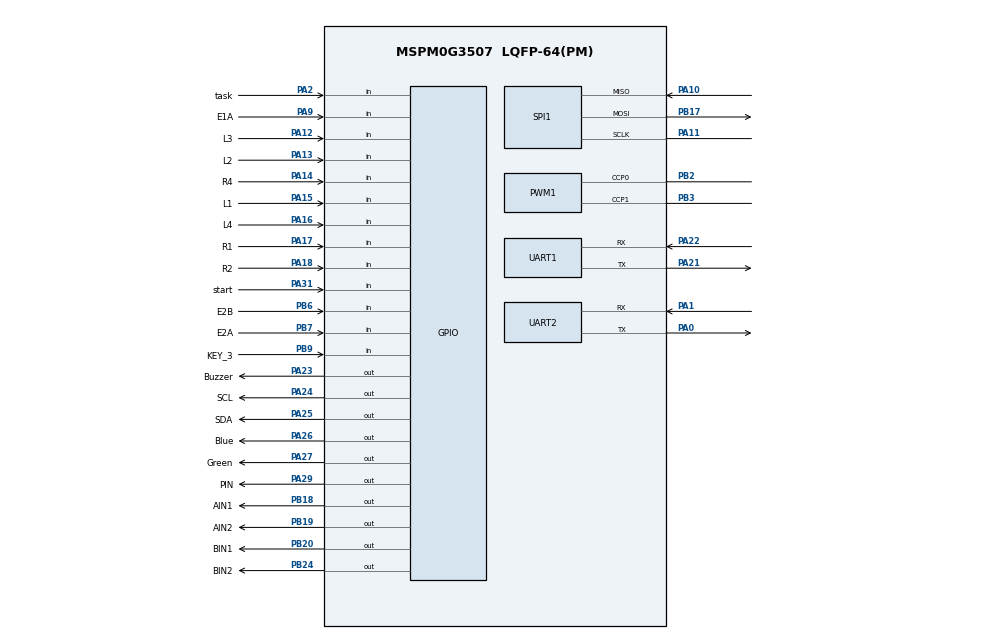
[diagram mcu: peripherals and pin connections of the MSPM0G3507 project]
/**
 * These arguments were used when this file was generated. They will be automatically applied on subsequent loads
 * via the GUI or CLI. Run CLI with '--help' for additional information on how to override these arguments.
 * @cliArgs --device "MSPM0G350X" --part "Default" --package "LQFP-64(PM)" --product "mspm0_sdk@2.02.00.05"
 * @v2CliArgs --device "MSPM0G3507" --package "LQFP-64(PM)" --product "mspm0_sdk@2.02.00.05"
 * @versions {"tool":"1.21.1+3772"}
 */

/**
 * Import the modules used in this configuration.
 */
const GPIO    = scripting.addModule("/ti/driverlib/GPIO", {}, false);
const GPIO1   = GPIO.addInstance();
const GPIO2   = GPIO.addInstance();
const GPIO3   = GPIO.addInstance();
const GPIO4   = GPIO.addInstance();
const GPIO5   = GPIO.addInstance();
const GPIO6   = GPIO.addInstance();
const GPIO7   = GPIO.addInstance();
const GPIO8   = GPIO.addInstance();
const GPIO9   = GPIO.addInstance();
const GPIO10  = GPIO.addInstance();
const GPIO11  = GPIO.addInstance();
const GPIO12  = GPIO.addInstance();
const GPIO13  = GPIO.addInstance();
const PWM     = scripting.addModule("/ti/driverlib/PWM", {}, false);
const PWM1    = PWM.addInstance();
const SPI     = scripting.addModule("/ti/driverlib/SPI", {}, false);
const SPI1    = SPI.addInstance();
const SYSCTL  = scripting.addModule("/ti/driverlib/SYSCTL");
const SYSTICK = scripting.addModule("/ti/driverlib/SYSTICK");
const TIMER   = scripting.addModule("/ti/driverlib/TIMER", {}, false);
const TIMER1  = TIMER.addInstance();
const TIMER2  = TIMER.addInstance();
const TIMER3  = TIMER.addInstance();
const TIMER4  = TIMER.addInstance();
const UART    = scripting.addModule("/ti/driverlib/UART", {}, false);
const UART1   = UART.addInstance();
const UART2   = UART.addInstance();

/**
 * Write custom configuration values to the imported modules.
 */
const divider9       = system.clockTree["UDIV"];
divider9.divideValue = 2;

const gate7  = system.clockTree["MFCLKGATE"];
gate7.enable = true;

const mux4       = system.clockTree["EXHFMUX"];
mux4.inputSelect = "EXHFMUX_XTAL";

const mux8       = system.clockTree["HSCLKMUX"];
mux8.inputSelect = "HSCLKMUX_SYSPLL2X";

const mux12       = system.clockTree["SYSPLLMUX"];
mux12.inputSelect = "zSYSPLLMUX_HFCLK";

const pinFunction4     = system.clockTree["HFXT"];
pinFunction4.inputFreq = 40;
pinFunction4.enable    = true;

GPIO1.port                               = "PORTA";
GPIO1.$name                              = "LED";
GPIO1.associatedPins.create(2);
GPIO1.associatedPins[0].internalResistor = "PULL_DOWN";
GPIO1.associatedPins[0].$name            = "Blue";
GPIO1.associatedPins[0].assignedPin      = "26";
GPIO1.associatedPins[0].pin.$assign      = "PA26";
GPIO1.associatedPins[1].$name            = "Green";
GPIO1.associatedPins[1].assignedPin      = "27";
GPIO1.associatedPins[1].pin.$assign      = "PA27";

const Board = scripting.addModule("/ti/driverlib/Board", {}, false);

GPIO2.port                               = "PORTA";
GPIO2.$name                              = "KEY";
GPIO2.associatedPins.create(2);
GPIO2.associatedPins[0].direction        = "INPUT";
GPIO2.associatedPins[0].$name            = "task";
GPIO2.associatedPins[0].internalResistor = "PULL_UP";
GPIO2.associatedPins[0].inputFilter      = "8_CYCLES";
GPIO2.associatedPins[0].assignedPin      = "02";
GPIO2.associatedPins[0].pin.$assign      = "PA2";
GPIO2.associatedPins[1].direction        = "INPUT";
GPIO2.associatedPins[1].$name            = "start";
GPIO2.associatedPins[1].internalResistor = "PULL_UP";
GPIO2.associatedPins[1].inputFilter      = "8_CYCLES";
GPIO2.associatedPins[1].assignedPin      = "31";
GPIO2.associatedPins[1].pin.$assign      = "PA31";

GPIO3.port                           = "PORTA";
GPIO3.$name                          = "BUZZER";
GPIO3.associatedPins[0].$name        = "Buzzer";
GPIO3.associatedPins[0].assignedPin  = "23";
GPIO3.associatedPins[0].initialValue = "SET";
GPIO3.associatedPins[0].pin.$assign  = "PA23";

GPIO4.$name                          = "Motor_left";
GPIO4.port                           = "PORTB";
GPIO4.associatedPins.create(2);
GPIO4.associatedPins[0].initialValue = "SET";
GPIO4.associatedPins[0].$name        = "AIN1";
GPIO4.associatedPins[0].assignedPin  = "18";
GPIO4.associatedPins[0].pin.$assign  = "PB18";
GPIO4.associatedPins[1].$name        = "AIN2";
GPIO4.associatedPins[1].initialValue = "SET";
GPIO4.associatedPins[1].assignedPin  = "19";
GPIO4.associatedPins[1].pin.$assign  = "PB19";

GPIO5.$name                          = "Motor_right";
GPIO5.associatedPins.create(2);
GPIO5.associatedPins[0].$name        = "BIN1";
GPIO5.associatedPins[0].initialValue = "SET";
GPIO5.associatedPins[0].assignedPort = "PORTB";
GPIO5.associatedPins[0].assignedPin  = "20";
GPIO5.associatedPins[0].pin.$assign  = "PB20";
GPIO5.associatedPins[1].$name        = "BIN2";
GPIO5.associatedPins[1].initialValue = "SET";
GPIO5.associatedPins[1].assignedPort = "PORTB";
GPIO5.associatedPins[1].assignedPin  = "24";
GPIO5.associatedPins[1].pin.$assign  = "PB24";

GPIO6.$name                               = "Encoder_left";
GPIO6.port                                = "PORTA";
GPIO6.associatedPins.create(2);
GPIO6.associatedPins[0].direction         = "INPUT";
GPIO6.associatedPins[0].$name             = "E1A";
GPIO6.associatedPins[0].assignedPin       = "9";
GPIO6.associatedPins[0].interruptEn       = true;
GPIO6.associatedPins[0].interruptPriority = "0";
GPIO6.associatedPins[0].polarity          = "RISE";
GPIO6.associatedPins[0].pin.$assign       = "PA9";
GPIO6.associatedPins[1].$name             = "E1B";
GPIO6.associatedPins[1].direction         = "INPUT";
GPIO6.associatedPins[1].assignedPin       = "8";
GPIO6.associatedPins[1].interruptEn       = true;
GPIO6.associatedPins[1].interruptPriority = "0";
GPIO6.associatedPins[1].polarity          = "RISE";

GPIO7.$name                               = "Encoder_right";
GPIO7.port                                = "PORTB";
GPIO7.associatedPins.create(2);
GPIO7.associatedPins[0].$name             = "E2A";
GPIO7.associatedPins[0].direction         = "INPUT";
GPIO7.associatedPins[0].interruptEn       = true;
GPIO7.associatedPins[0].assignedPin       = "7";
GPIO7.associatedPins[0].interruptPriority = "0";
GPIO7.associatedPins[0].polarity          = "RISE";
GPIO7.associatedPins[0].pin.$assign       = "PB7";
GPIO7.associatedPins[1].$name             = "E2B";
GPIO7.associatedPins[1].direction         = "INPUT";
GPIO7.associatedPins[1].interruptEn       = true;
GPIO7.associatedPins[1].assignedPin       = "6";
GPIO7.associatedPins[1].interruptPriority = "0";
GPIO7.associatedPins[1].polarity          = "RISE";
GPIO7.associatedPins[1].pin.$assign       = "PB6";

GPIO8.port                          = "PORTA";
GPIO8.$name                         = "Gray_IOA";
GPIO8.associatedPins.create(7);
GPIO8.associatedPins[0].direction   = "INPUT";
GPIO8.associatedPins[0].$name       = "L4";
GPIO8.associatedPins[0].assignedPin = "16";
GPIO8.associatedPins[0].pin.$assign = "PA16";
GPIO8.associatedPins[1].direction   = "INPUT";
GPIO8.associatedPins[1].$name       = "L3";
GPIO8.associatedPins[1].assignedPin = "12";
GPIO8.associatedPins[1].pin.$assign = "PA12";
GPIO8.associatedPins[2].direction   = "INPUT";
GPIO8.associatedPins[2].$name       = "L2";
GPIO8.associatedPins[2].assignedPin = "13";
GPIO8.associatedPins[2].pin.$assign = "PA13";
GPIO8.associatedPins[3].direction   = "INPUT";
GPIO8.associatedPins[3].$name       = "L1";
GPIO8.associatedPins[3].assignedPin = "15";
GPIO8.associatedPins[3].pin.$assign = "PA15";
GPIO8.associatedPins[4].direction   = "INPUT";
GPIO8.associatedPins[4].assignedPin = "17";
GPIO8.associatedPins[4].$name       = "R1";
GPIO8.associatedPins[4].pin.$assign = "PA17";
GPIO8.associatedPins[5].direction   = "INPUT";
GPIO8.associatedPins[5].assignedPin = "18";
GPIO8.associatedPins[5].$name       = "R2";
GPIO8.associatedPins[5].pin.$assign = "PA18";
GPIO8.associatedPins[6].$name       = "R4";
GPIO8.associatedPins[6].assignedPin = "14";
GPIO8.associatedPins[6].direction   = "INPUT";
GPIO8.associatedPins[6].pin.$assign = "PA14";

GPIO9.port                          = "PORTB";
GPIO9.$name                         = "Gray_IOB";
GPIO9.associatedPins[0].direction   = "INPUT";
GPIO9.associatedPins[0].assignedPin = "08";
GPIO9.associatedPins[0].$name       = "R3";

GPIO10.$name                          = "SR04";
GPIO10.associatedPins.create(2);
GPIO10.associatedPins[0].$name        = "Trig";
GPIO10.associatedPins[0].initialValue = "SET";
GPIO10.associatedPins[0].assignedPort = "PORTA";
GPIO10.associatedPins[0].assignedPin  = "7";
GPIO10.associatedPins[1].$name        = "Echo";
GPIO10.associatedPins[1].assignedPort = "PORTA";
GPIO10.associatedPins[1].assignedPin  = "28";
GPIO10.associatedPins[1].initialValue = "SET";
GPIO10.associatedPins[1].direction    = "INPUT";

GPIO11.$name                         = "KEY3";
GPIO11.port                          = "PORTB";
GPIO11.associatedPins[0].$name       = "KEY_3";
GPIO11.associatedPins[0].direction   = "INPUT";
GPIO11.associatedPins[0].assignedPin = "9";
GPIO11.associatedPins[0].pin.$assign = "PB9";

GPIO12.$name                          = "OLED";
GPIO12.port                           = "PORTA";
GPIO12.associatedPins.create(2);
GPIO12.associatedPins[0].$name        = "SCL";
GPIO12.associatedPins[0].initialValue = "SET";
GPIO12.associatedPins[0].assignedPin  = "24";
GPIO12.associatedPins[0].pin.$assign  = "PA24";
GPIO12.associatedPins[1].$name        = "SDA";
GPIO12.associatedPins[1].initialValue = "SET";
GPIO12.associatedPins[1].assignedPin  = "25";
GPIO12.associatedPins[1].pin.$assign  = "PA25";

GPIO13.$name                          = "CS";
GPIO13.associatedPins[0].$name        = "PIN";
GPIO13.associatedPins[0].assignedPort = "PORTA";
GPIO13.associatedPins[0].assignedPin  = "29";
GPIO13.associatedPins[0].pin.$assign  = "PA29";

PWM1.$name                              = "PWM";
PWM1.clockDivider                       = 8;
PWM1.pwmMode                            = "EDGE_ALIGN_UP";
PWM1.timerStartTimer                    = true;
PWM1.clockPrescale                      = 4;
PWM1.peripheral.$assign                 = "TIMG6";
PWM1.peripheral.ccp0Pin.$assign         = "PB2";
PWM1.peripheral.ccp1Pin.$assign         = "PB3";
PWM1.PWM_CHANNEL_0.$name                = "ti_driverlib_pwm_PWMTimerCC0";
PWM1.PWM_CHANNEL_1.$name                = "ti_driverlib_pwm_PWMTimerCC1";
PWM1.ccp0PinConfig.direction            = scripting.forceWrite("OUTPUT");
PWM1.ccp0PinConfig.hideOutputInversion  = scripting.forceWrite(false);
PWM1.ccp0PinConfig.onlyInternalResistor = scripting.forceWrite(false);
PWM1.ccp0PinConfig.passedPeripheralType = scripting.forceWrite("Digital");
PWM1.ccp0PinConfig.$name                = "ti_driverlib_gpio_GPIOPinGeneric2";
PWM1.ccp1PinConfig.direction            = scripting.forceWrite("OUTPUT");
PWM1.ccp1PinConfig.hideOutputInversion  = scripting.forceWrite(false);
PWM1.ccp1PinConfig.onlyInternalResistor = scripting.forceWrite(false);
PWM1.ccp1PinConfig.passedPeripheralType = scripting.forceWrite("Digital");
PWM1.ccp1PinConfig.$name                = "ti_driverlib_gpio_GPIOPinGeneric3";

SPI1.$name                              = "SPI";
SPI1.targetBitRate                      = 2000000;
SPI1.polarity                           = "1";
SPI1.phase                              = "1";
SPI1.peripheral.$assign                 = "SPI0";
SPI1.peripheral.sclkPin.$assign         = "PA11";
SPI1.peripheral.mosiPin.$assign         = "PB17";
SPI1.peripheral.misoPin.$assign         = "PA10";
SPI1.sclkPinConfig.direction            = scripting.forceWrite("OUTPUT");
SPI1.sclkPinConfig.onlyInternalResistor = scripting.forceWrite(false);
SPI1.sclkPinConfig.passedPeripheralType = scripting.forceWrite("Digital");
SPI1.sclkPinConfig.$name                = "ti_driverlib_gpio_GPIOPinGeneric6";
SPI1.mosiPinConfig.direction            = scripting.forceWrite("OUTPUT");
SPI1.mosiPinConfig.hideOutputInversion  = scripting.forceWrite(false);
SPI1.mosiPinConfig.onlyInternalResistor = scripting.forceWrite(false);
SPI1.mosiPinConfig.passedPeripheralType = scripting.forceWrite("Digital");
SPI1.mosiPinConfig.$name                = "ti_driverlib_gpio_GPIOPinGeneric7";
SPI1.misoPinConfig.onlyInternalResistor = scripting.forceWrite(false);
SPI1.misoPinConfig.passedPeripheralType = scripting.forceWrite("Digital");
SPI1.misoPinConfig.$name                = "ti_driverlib_gpio_GPIOPinGeneric8";
SPI1.cs0PinConfig.direction             = scripting.forceWrite("OUTPUT");
SPI1.cs0PinConfig.hideOutputInversion   = scripting.forceWrite(false);
SPI1.cs0PinConfig.onlyInternalResistor  = scripting.forceWrite(false);
SPI1.cs0PinConfig.passedPeripheralType  = scripting.forceWrite("Digital");
SPI1.cs0PinConfig.$name                 = "ti_driverlib_gpio_GPIOPinGeneric9";

SYSCTL.forceDefaultClkConfig = true;
SYSCTL.clockTreeEn           = true;

SYSTICK.periodEnable      = true;
SYSTICK.systickEnable     = true;
SYSTICK.interruptPriority = "0";
SYSTICK.period            = 32;

TIMER1.$name              = "TIMER_0";
TIMER1.timerClkDiv        = 8;
TIMER1.timerClkPrescale   = 100;
TIMER1.timerMode          = "PERIODIC";
TIMER1.interrupts         = ["ZERO"];
TIMER1.timerStartTimer    = true;
TIMER1.timerPeriod        = "10ms";
TIMER1.interruptPriority  = "0";
TIMER1.peripheral.$assign = "TIMA0";

TIMER2.$name              = "TIMER_1";
TIMER2.timerStartTimer    = true;
TIMER2.timerMode          = "PERIODIC";
TIMER2.timerClkDiv        = 8;
TIMER2.timerClkPrescale   = 100;
TIMER2.interrupts         = ["LOAD"];
TIMER2.interruptPriority  = "1";
TIMER2.timerPeriod        = "10ms";
TIMER2.peripheral.$assign = "TIMG0";

TIMER3.$name              = "TIMER_2";
TIMER3.timerClkDiv        = 4;
TIMER3.timerClkPrescale   = 10;
TIMER3.timerMode          = "PERIODIC_UP";
TIMER3.timerStartTimer    = true;
TIMER3.timerPeriod        = "1ms";
TIMER3.interruptPriority  = "2";
TIMER3.interrupts         = ["LOAD"];
TIMER3.peripheral.$assign = "TIMA1";

TIMER4.$name              = "TIMER_3";
TIMER4.timerMode          = "PERIODIC";
TIMER4.timerPeriod        = "100us";
TIMER4.timerStartTimer    = true;
TIMER4.interrupts         = ["ZERO"];
TIMER4.interruptPriority  = "2";
TIMER4.peripheral.$assign = "TIMG7";

UART1.$name                            = "UART_2";
UART1.targetBaudRate                   = 115200;
UART1.enabledInterrupts                = ["RX"];
UART1.interruptPriority                = "0";
UART1.uartClkSrc                       = "MFCLK";
UART1.peripheral.$assign               = "UART2";
UART1.peripheral.rxPin.$assign         = "PA22";
UART1.peripheral.txPin.$assign         = "PA21";
UART1.txPinConfig.direction            = scripting.forceWrite("OUTPUT");
UART1.txPinConfig.hideOutputInversion  = scripting.forceWrite(false);
UART1.txPinConfig.onlyInternalResistor = scripting.forceWrite(false);
UART1.txPinConfig.passedPeripheralType = scripting.forceWrite("Digital");
UART1.txPinConfig.$name                = "ti_driverlib_gpio_GPIOPinGeneric0";
UART1.rxPinConfig.hideOutputInversion  = scripting.forceWrite(false);
UART1.rxPinConfig.onlyInternalResistor = scripting.forceWrite(false);
UART1.rxPinConfig.passedPeripheralType = scripting.forceWrite("Digital");
UART1.rxPinConfig.$name                = "ti_driverlib_gpio_GPIOPinGeneric1";

UART2.$name                            = "UART_0";
UART2.targetBaudRate                   = 115200;
UART2.enabledInterrupts                = ["RX"];
UART2.interruptPriority                = "1";
UART2.peripheral.$assign               = "UART0";
UART2.peripheral.rxPin.$assign         = "PA1";
UART2.peripheral.txPin.$assign         = "PA0";
UART2.txPinConfig.direction            = scripting.forceWrite("OUTPUT");
UART2.txPinConfig.hideOutputInversion  = scripting.forceWrite(false);
UART2.txPinConfig.onlyInternalResistor = scripting.forceWrite(false);
UART2.txPinConfig.passedPeripheralType = scripting.forceWrite("Digital");
UART2.txPinConfig.$name                = "ti_driverlib_gpio_GPIOPinGeneric4";
UART2.rxPinConfig.hideOutputInversion  = scripting.forceWrite(false);
UART2.rxPinConfig.onlyInternalResistor = scripting.forceWrite(false);
UART2.rxPinConfig.passedPeripheralType = scripting.forceWrite("Digital");
UART2.rxPinConfig.$name                = "ti_driverlib_gpio_GPIOPinGeneric5";

/**
 * Pinmux solution for unlocked pins/peripherals. This ensures that minor changes to the automatic solver in a future
 * version of the tool will not impact the pinmux you originally saw.  These lines can be completely deleted in order to
 * re-solve from scratch.
 */
pinFunction4.peripheral.$suggestSolution           = "SYSCTL";
pinFunction4.peripheral.hfxInPin.$suggestSolution  = "PA5";
pinFunction4.peripheral.hfxOutPin.$suggestSolution = "PA6";
Board.peripheral.$suggestSolution                  = "DEBUGSS";
Board.peripheral.swclkPin.$suggestSolution         = "PA20";
Board.peripheral.swdioPin.$suggestSolution         = "PA19";
GPIO6.associatedPins[1].pin.$suggestSolution       = "PA8";
GPIO9.associatedPins[0].pin.$suggestSolution       = "PB8";
GPIO10.associatedPins[0].pin.$suggestSolution      = "PA7";
GPIO10.associatedPins[1].pin.$suggestSolution      = "PA28";
SPI1.peripheral.cs0Pin.$suggestSolution            = "PB25";
